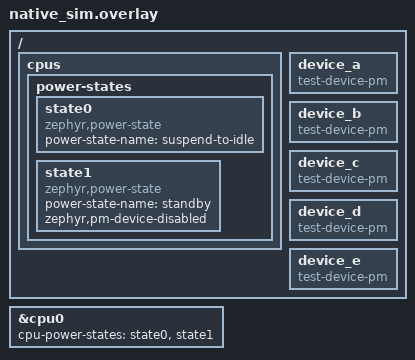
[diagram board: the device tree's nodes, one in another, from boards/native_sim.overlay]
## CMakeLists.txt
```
# Copyright (c) 2020 Intel Corporation.
# Copyright 2026 NXP
# SPDX-License-Identifier: Apache-2.0

cmake_minimum_required(VERSION 3.28.0)
find_package(Zephyr REQUIRED HINTS $ENV{ZEPHYR_BASE})
project(power_management_test)

FILE(GLOB app_sources src/*.c)
target_sources(app PRIVATE ${app_sources})

if(CONFIG_TEST_PM_TIMER_RESTART)
  if(NOT LINKER MATCHES "^(ld|lld)$")
    message(FATAL_ERROR "The timer resume test requires GNU ld or LLD for --wrap")
  endif()
  target_link_options(app PUBLIC "LINKER:--wrap=sys_clock_idle_exit")
endif()

target_include_directories(app
  PRIVATE
    ${ZEPHYR_BASE}/kernel/include
    ${ZEPHYR_BASE}/arch/${ARCH}/include
)
```

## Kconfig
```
# Copyright (c) 2023 Nordic Semiconductor ASA
# Copyright 2026 NXP
# SPDX-License-Identifier: Apache-2.0

menu "Zephyr"
source "Kconfig.zephyr"
endmenu

config TEST_PROVIDE_PM_HOOKS
	bool "Provide PM hooks for test purposes"
	default y
	select HAS_PM

config TEST_PM_TIMER_RESTART
	bool "Test timer and PM resume ordering"
	# The test relies on SysTick stopping its cycle counter for an infinite idle
	# timeout with no LPM companion, then restarting it on idle exit.
	depends on CORTEX_M_SYSTICK
```

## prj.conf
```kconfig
CONFIG_ZTEST=y
CONFIG_PM=y
CONFIG_PM_DEVICE=y
CONFIG_PM_DEVICE_RUNTIME=y
CONFIG_PM_POLICY_CUSTOM=y
CONFIG_MP_MAX_NUM_CPUS=1
CONFIG_PM_DEVICE_SYSTEM_MANAGED=y
CONFIG_STATS=y
CONFIG_PM_STATS=y
```

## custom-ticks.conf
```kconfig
CONFIG_ZTEST=y
CONFIG_PM=y
CONFIG_PM_DEVICE=y
CONFIG_PM_DEVICE_RUNTIME=y
CONFIG_PM_POLICY_CUSTOM=y
CONFIG_MP_MAX_NUM_CPUS=1
CONFIG_PM_DEVICE_SYSTEM_MANAGED=y
CONFIG_STATS=y
CONFIG_PM_STATS=y
CONFIG_PM_CUSTOM_TICKS_HOOK=y
```

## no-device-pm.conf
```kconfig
CONFIG_ZTEST=y
CONFIG_PM=y
CONFIG_PM_DEVICE=y
CONFIG_PM_DEVICE_RUNTIME=y
CONFIG_PM_POLICY_CUSTOM=y
CONFIG_PM_DEVICE_SYSTEM_MANAGED=n
CONFIG_MP_MAX_NUM_CPUS=1
```

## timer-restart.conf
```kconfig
# SPDX-FileCopyrightText: Copyright 2026 NXP
# SPDX-License-Identifier: Apache-2.0

CONFIG_ZTEST=y
CONFIG_PM=y
CONFIG_PM_DEVICE=y
CONFIG_PM_DEVICE_RUNTIME=y
CONFIG_PM_POLICY_CUSTOM=y
CONFIG_MP_MAX_NUM_CPUS=1
CONFIG_PM_DEVICE_SYSTEM_MANAGED=y
CONFIG_STATS=y
CONFIG_PM_STATS=y
CONFIG_TEST_PM_TIMER_RESTART=y
CONFIG_SYSTEM_TIMER_LPM_COMPANION_NONE=y
```

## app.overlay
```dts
/*
 * Copyright 2021 Intel Corporation
 *
 * SPDX-License-Identifier: Apache-2.0
 */

/ {
	wakeup_capable_test_dev {
		compatible = "zephyr,wakeup-dev";
		label = "WAKEUP_CAPABLE";
		status = "okay";
		wakeup-source;
	};
};
```

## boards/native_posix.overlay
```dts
/*
 * Copyright (c) 2021 Intel Corporation.
 *
 * SPDX-License-Identifier: Apache-2.0
 */

/ {
	cpus {
		power-states {
			suspend: suspend {
				compatible = "zephyr,power-state";
				power-state-name = "suspend-to-idle";
			};
		};
	};

	device_a: device_a {
		compatible = "test-device-pm";
	};

	device_b: device_b {
		compatible = "test-device-pm";
	};

	device_c: device_c {
		compatible = "test-device-pm";
	};

	device_d: device_d {
		compatible = "test-device-pm";
	};
};

&cpu0 {
	cpu-power-states = <&suspend>;
};
```

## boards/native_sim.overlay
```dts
/*
 * Copyright (c) 2021 Intel Corporation.
 *
 * SPDX-License-Identifier: Apache-2.0
 */

/ {
	cpus {
		power-states {
			state0: state0 {
				compatible = "zephyr,power-state";
				power-state-name = "suspend-to-idle";
			};

			state1: state1 {
				compatible = "zephyr,power-state";
				power-state-name = "standby";
				zephyr,pm-device-disabled;
			};
		};
	};

	device_a: device_a {
		compatible = "test-device-pm";
	};

	device_b: device_b {
		compatible = "test-device-pm";
	};

	device_c: device_c {
		compatible = "test-device-pm";
	};

	device_d: device_d {
		compatible = "test-device-pm";
	};

	device_e: device_e {
		compatible = "test-device-pm";
	};
};

&cpu0 {
	cpu-power-states = <&state0 &state1>;
};
```

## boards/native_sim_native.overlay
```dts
/*
 * Copyright (c) 2021 Intel Corporation.
 *
 * SPDX-License-Identifier: Apache-2.0
 */

/ {
	device_a: device_a {
		compatible = "test-device-pm";
	};

	device_b: device_b {
		compatible = "test-device-pm";
	};

	device_c: device_c {
		compatible = "test-device-pm";
	};

	device_d: device_d {
		compatible = "test-device-pm";
	};
};
```

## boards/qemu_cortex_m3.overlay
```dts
/*
 * SPDX-FileCopyrightText: Copyright 2026 NXP
 *
 * SPDX-License-Identifier: Apache-2.0
 */

/ {
	cpus {
		power-states {
			state0: state0 {
				compatible = "zephyr,power-state";
				power-state-name = "suspend-to-idle";
			};

			state1: state1 {
				compatible = "zephyr,power-state";
				power-state-name = "standby";
				zephyr,pm-device-disabled;
			};
		};
	};

	device_a: device_a {
		compatible = "test-device-pm";
	};

	device_b: device_b {
		compatible = "test-device-pm";
	};

	device_c: device_c {
		compatible = "test-device-pm";
	};

	device_d: device_d {
		compatible = "test-device-pm";
	};

	device_e: device_e {
		compatible = "test-device-pm";
	};
};

&{/cpus/cpu@0} {
	cpu-power-states = <&state0 &state1>;
};
```

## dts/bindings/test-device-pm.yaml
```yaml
# Copyright (c) 2021, Intel Corporation
# SPDX-License-Identifier: Apache-2.0

description: |
    This binding provides resources required to build and run the
    tests/subsys/power/power_mgmt test in Zephyr.

compatible: "test-device-pm"
```

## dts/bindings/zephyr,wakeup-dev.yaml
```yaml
# Copyright (c) 2021 Intel Corporation.
# SPDX-License-Identifier: Apache-2.0

# Properties for Power Management (PM)

description: |
    This binding provides resources required to build and run the
    tests/subsys/power/power_mgmt test in Zephyr.

compatible: "zephyr,wakeup-dev"

include: base.yaml
```

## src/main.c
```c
/*
 * Copyright (c) 2020 Intel Corporation.
 * Copyright 2026 NXP
 *
 * SPDX-License-Identifier: Apache-2.0
 */

#include <zephyr/sys/printk.h>
#include <zephyr/types.h>
#include <zephyr/pm/device.h>
#include <zephyr/pm/device_runtime.h>
#include <zephyr/ztest.h>
#include <ksched.h>
#include <zephyr/kernel.h>
#include <zephyr/drivers/timer/system_timer.h>
#include <zephyr/pm/pm.h>
#include <zephyr/pm/policy.h>
#include "dummy_driver.h"

/**
 * @brief Power Management Tests
 * @defgroup power_tests Power Management
 * @ingroup all_tests
 */

#define SLEEP_MSEC 100
#define SLEEP_TIMEOUT K_MSEC(SLEEP_MSEC)

/* for checking power suspend and resume order between system and devices */
static bool enter_low_power;
static bool notify_app_entry;
static bool notify_app_exit;
static bool set_pm;
static bool leave_idle;
static bool idle_entered;
static bool testing_device_runtime;
static bool testing_device_order;
static bool testing_force_state;
static bool exit_post_ops_called;
static int32_t policy_ticks;
#ifdef CONFIG_TEST_PM_TIMER_RESTART
static bool testing_timer_restart;
static bool resume_timer_progressed;

enum resume_event {
	RESUME_POST_OPS,
	RESUME_TIMER,
	RESUME_DEVICE,
	RESUME_NOTIFY,
};

static enum resume_event resume_events[4];
static size_t resume_event_count;

static void record_resume_event(enum resume_event event)
{
	zassert_false(arch_cpu_irqs_are_enabled(), "Interrupts enabled during resume");
	zassert_true(resume_event_count < ARRAY_SIZE(resume_events),
		     "Too many resume events");
	resume_events[resume_event_count++] = event;
}

void __real_sys_clock_idle_exit(void);

void __wrap_sys_clock_idle_exit(void)
{
	if (testing_timer_restart) {
		record_resume_event(RESUME_TIMER);
	}
	__real_sys_clock_idle_exit();
}

static void notify_timer_test_exit(enum pm_state state)
{
	ARG_UNUSED(state);
	record_resume_event(RESUME_NOTIFY);
}

static struct pm_notifier timer_test_notifier = {
	.state_exit = notify_timer_test_exit,
};
#endif

enum pm_state forced_state;
static const struct device *device_dummy;
static struct dummy_driver_api *api;

static const struct device *const device_a =
	DEVICE_DT_GET(DT_INST(0, test_device_pm));
static const struct device *const device_c =
	DEVICE_DT_GET(DT_INST(2, test_device_pm));

/*
 * This device does not support PM. It is used to check
 * the behavior of the PM subsystem when a device does not
 * support PM.
 */
static const struct device *const device_e =
	DEVICE_DT_GET(DT_INST(4, test_device_pm));

DEVICE_DT_DEFINE(DT_INST(4, test_device_pm), NULL,
		NULL, NULL, NULL,
		PRE_KERNEL_1, CONFIG_KERNEL_INIT_PRIORITY_DEVICE,
		NULL);

/*
 * According with the initialization level, devices A, B and C are
 * initialized in the following order A -> B -> C.
 *
 * The power management subsystem uses this order to suspend and resume
 * devices. Devices are suspended in the reverse order:
 *
 * C -> B -> A
 *
 * While resuming uses the initialization order:
 *
 * A -> B -> C
 *
 * This test checks if these order is correct checking devices A and C states
 * when suspending / resuming device B.
 */

static int device_a_pm_action(const struct device *dev,
		enum pm_device_action pm_action)
{
	ARG_UNUSED(dev);
	ARG_UNUSED(pm_action);

	return 0;
}

PM_DEVICE_DT_DEFINE(DT_INST(0, test_device_pm), device_a_pm_action);

DEVICE_DT_DEFINE(DT_INST(0, test_device_pm), NULL,
		PM_DEVICE_DT_GET(DT_INST(0, test_device_pm)), NULL, NULL,
		PRE_KERNEL_1, CONFIG_KERNEL_INIT_PRIORITY_DEVICE,
		NULL);


static int device_b_pm_action(const struct device *dev,
		enum pm_device_action pm_action)
{
	enum pm_device_state state_a;
	enum pm_device_state state_c;

#ifdef CONFIG_TEST_PM_TIMER_RESTART
	if ((pm_action == PM_DEVICE_ACTION_RESUME) && testing_timer_restart) {
		uint32_t start_cycles = k_cycle_get_32();

		for (volatile uint32_t i = 0U; i < 10000U; i++) {
			arch_nop();
		}

		resume_timer_progressed = k_cycle_get_32() != start_cycles;
		record_resume_event(RESUME_DEVICE);
	}
#endif

	if (!testing_device_order) {
		return 0;
	}

	(void)pm_device_state_get(device_a, &state_a);
	(void)pm_device_state_get(device_c, &state_c);

	switch (pm_action) {
	case PM_DEVICE_ACTION_RESUME:
		/* Check if device C is still suspended */
		zassert_equal(state_c, PM_DEVICE_STATE_SUSPENDED,
				"Inconsistent states");
		/* Check if device A is already active */
		zassert_equal(state_a, PM_DEVICE_STATE_ACTIVE,
				"Inconsistent states");
		break;
	case PM_DEVICE_ACTION_SUSPEND:
		/* Check if device C is already suspended */
		zassert_equal(state_c, PM_DEVICE_STATE_SUSPENDED,
				"Inconsistent states");
		/* Check if device A is still active */
		zassert_equal(state_a, PM_DEVICE_STATE_ACTIVE,
				"Inconsistent states");
		break;
	default:
		break;
	}

	return 0;
}

PM_DEVICE_DT_DEFINE(DT_INST(1, test_device_pm), device_b_pm_action);

DEVICE_DT_DEFINE(DT_INST(1, test_device_pm), NULL,
		PM_DEVICE_DT_GET(DT_INST(1, test_device_pm)), NULL, NULL,
		PRE_KERNEL_2, CONFIG_KERNEL_INIT_PRIORITY_DEVICE,
		NULL);

static int device_c_pm_action(const struct device *dev,
		enum pm_device_action pm_action)
{
	ARG_UNUSED(dev);
	ARG_UNUSED(pm_action);

	return 0;
}

PM_DEVICE_DT_DEFINE(DT_INST(2, test_device_pm), device_c_pm_action);

DEVICE_DT_DEFINE(DT_INST(2, test_device_pm), NULL,
		PM_DEVICE_DT_GET(DT_INST(2, test_device_pm)), NULL, NULL,
		POST_KERNEL, CONFIG_KERNEL_INIT_PRIORITY_DEVICE,
		NULL);

static int device_init_failed(const struct device *dev)
{
	ARG_UNUSED(dev);

	/* Return error to mark device as not ready. */
	return -EIO;
}

static int device_d_pm_action(const struct device *dev,
		enum pm_device_action pm_action)
{
	ARG_UNUSED(dev);
	ARG_UNUSED(pm_action);

	zassert_unreachable("Entered PM handler for unready device");

	return 0;
}

PM_DEVICE_DT_DEFINE(DT_INST(3, test_device_pm), device_d_pm_action);

DEVICE_DT_DEFINE(DT_INST(3, test_device_pm), device_init_failed,
		PM_DEVICE_DT_GET(DT_INST(3, test_device_pm)), NULL, NULL,
		POST_KERNEL, CONFIG_KERNEL_INIT_PRIORITY_DEVICE,
		NULL);

void pm_state_set(enum pm_state state, uint8_t substate_id)
{
	ARG_UNUSED(substate_id);
	ARG_UNUSED(state);

	if (!IS_ENABLED(CONFIG_PM_STATE_SET_IRQ_UNLOCKED)) {
		zassert_equal(_kernel.idle, 0,
			      "PM state set ran before idle wake sentinel was cleared");
	}

#ifdef CONFIG_TEST_PM_TIMER_RESTART
	if (testing_timer_restart) {
		k_spinlock_key_t key = sys_clock_lock();

		sys_clock_idle_enter(SYS_CLOCK_IDLE_FOREVER);
		sys_clock_unlock(key);
		return;
	}
#endif

	enum pm_device_state device_power_state;

#ifndef CONFIG_PM_DEVICE_SYSTEM_MANAGED
	/* Devices shouldn't have changed state because system managed
	 * device power management is not enabled.
	 **/
	pm_device_state_get(device_a, &device_power_state);
	zassert_true(device_power_state == PM_DEVICE_STATE_ACTIVE);

	pm_device_state_get(device_c, &device_power_state);
	zassert_true(device_power_state == PM_DEVICE_STATE_ACTIVE);
#else
	/* If testing device order this function does not need to anything */
	if (testing_device_order) {
		return;
	}

	if (testing_force_state) {
		/* if forced to given power state was called */
		set_pm = true;
		zassert_equal(state, forced_state);
		testing_force_state = false;

		/* We have forced a state that does not trigger device power management.
		 * The device should still be active.
		 */
		pm_device_state_get(device_c, &device_power_state);
		zassert_true(device_power_state == PM_DEVICE_STATE_ACTIVE);
	}

	/* at this point, notify_pm_state_entry() implemented in
	 * this file has been called and set_pm should have been set
	 */
	zassert_true(set_pm == true,
		     "Notification to enter suspend was not sent to the App");

	/* this function is called after devices enter low power state */
	pm_device_state_get(device_dummy, &device_power_state);

	if (testing_device_runtime) {
		/* If device runtime is enable, the device should still be
		 * active
		 */
		zassert_true(device_power_state == PM_DEVICE_STATE_ACTIVE);
	} else {
		/* at this point, devices have been deactivated */
		zassert_false(device_power_state == PM_DEVICE_STATE_ACTIVE);
	}

	/* this function is called when system entering low power state, so
	 * parameter state should not be PM_STATE_ACTIVE
	 */
	zassert_false(state == PM_STATE_ACTIVE,
		      "Entering low power state with a wrong parameter");
#endif
}

void pm_state_exit_post_ops(enum pm_state state, uint8_t substate_id)
{
	ARG_UNUSED(state);
	ARG_UNUSED(substate_id);

	exit_post_ops_called = true;
#ifdef CONFIG_TEST_PM_TIMER_RESTART
	if (testing_timer_restart) {
		record_resume_event(RESUME_POST_OPS);
	}
#endif
	zassert_false(arch_cpu_irqs_are_enabled(),
		      "PM exit post ops ran with interrupts enabled");
}

#ifdef CONFIG_PM_CUSTOM_TICKS_HOOK
/* Ticks reported by the custom hook; -1 means no custom event is pending */
static int64_t custom_ticks = -1;

int64_t pm_policy_next_custom_ticks(void)
{
	return custom_ticks;
}
#endif /* CONFIG_PM_CUSTOM_TICKS_HOOK */

/* Our PM policy handler */
const struct pm_state_info *pm_policy_next_state(uint8_t cpu, int32_t ticks)
{
	const struct pm_state_info *cpu_states;

	policy_ticks = ticks;

	zassert_true(pm_state_cpu_get_all(cpu, &cpu_states) == 2,
		     "There is no power state defined");

	/* make sure this is idle thread */
	zassert_true(z_is_idle_thread_object(_current));
	zassert_true(ticks == _kernel.idle);
	zassert_false(k_can_yield());
	idle_entered = true;

	if (enter_low_power) {
		enter_low_power = false;
		notify_app_entry = true;
		return &cpu_states[0];
	}

	return NULL;
}

/* implement in application, called by idle thread */
static void notify_pm_state_entry(enum pm_state state)
{
	enum pm_device_state device_power_state;

	/* enter suspend */
	zassert_true(notify_app_entry == true,
		     "Notification to enter suspend was not sent to the App");
	zassert_true(z_is_idle_thread_object(_current));
	zassert_equal(state, PM_STATE_SUSPEND_TO_IDLE);

	pm_device_state_get(device_dummy, &device_power_state);
	if (testing_device_runtime || !IS_ENABLED(CONFIG_PM_DEVICE_SYSTEM_MANAGED)) {
		/* If device runtime is enable, the device should still be
		 * active
		 */
		zassert_true(device_power_state == PM_DEVICE_STATE_ACTIVE);
	} else {
		/* at this point, devices should not be active */
		zassert_false(device_power_state == PM_DEVICE_STATE_ACTIVE);
	}
	set_pm = true;
	notify_app_exit = true;
}

/* implement in application, called by idle thread */
static void notify_pm_state_exit(enum pm_state state)
{
	enum pm_device_state device_power_state;

	/* leave suspend */
	zassert_true(notify_app_exit == true,
		     "Notification to leave suspend was not sent to the App");
	zassert_true(z_is_idle_thread_object(_current));
	zassert_equal(state, PM_STATE_SUSPEND_TO_IDLE);

	/* at this point, devices are active again*/
	pm_device_state_get(device_dummy, &device_power_state);
	zassert_equal(device_power_state, PM_DEVICE_STATE_ACTIVE);
	leave_idle = true;

}

/**
 * @brief test power idle
 *
 * @details
 *  - The global idle routine executes when no other work is available
 *  - The idle routine provide a timeout parameter to the suspend routine
 *    indicating the amount of time guaranteed to expire before the next
 *    timeout, pm_policy_next_state() handle this parameter.
 *  - In this case, pm_policy_next_sate() return PM_STATE_ACTIVE,
 *    so there is no low power operation happen.
 *
 * @see pm_policy_next_state()
 *
 * @ingroup power_tests
 * @verifies ZEP-SRS-13-41
 */
ZTEST(power_management_1cpu, test_power_idle)
{
	TC_PRINT("give way to idle thread\n");
	k_sleep(SLEEP_TIMEOUT);
	zassert_true(idle_entered, "Never entered idle thread");
}

/*
 * @brief test that a far future event does not truncate the policy tick count
 *
 * @details
 *  - pm_policy_next_event_ticks() reports the ticks until the next registered
 *    event as an int64_t, while pm_policy_next_state() takes an int32_t.
 *  - An event scheduled beyond the int32_t tick range must therefore be
 *    saturated, not truncated: a truncated value wraps negative, which both
 *    trips the assertions in the PM subsystem and makes the far future event
 *    look nearer than the kernel timeout.
 *  - The nearer kernel timeout must still be the one handed to the policy.
 *
 * @see pm_policy_event_register(), pm_policy_next_event_ticks()
 *
 * @ingroup power_tests
 */
ZTEST(power_management_1cpu, test_next_event_far_future_ticks)
{
	struct pm_policy_event evt;

	policy_ticks = -1;
	idle_entered = false;

	/*
	 * Schedule the event past the int32_t tick range, with a one second
	 * margin so that the remaining tick count is still out of range by the
	 * time the idle thread evaluates it. Using an uptime relative target
	 * keeps this independent of the tick rate.
	 */
	pm_policy_event_register(&evt, k_uptime_ticks() + (int64_t)INT32_MAX +
					      CONFIG_SYS_CLOCK_TICKS_PER_SEC);

	/* give way to idle thread */
	k_sleep(SLEEP_TIMEOUT);

	pm_policy_event_unregister(&evt);

	zassert_true(idle_entered, "Never entered idle thread");
	zassert_true(policy_ticks >= 0,
		     "Far future event truncated to a negative tick count: %d",
		     policy_ticks);
}

#ifdef CONFIG_PM_CUSTOM_TICKS_HOOK
/*
 * @brief test that a far future custom event does not truncate the policy ticks
 *
 * @details
 *  - pm_policy_next_custom_ticks() reports int64_t ticks and has the same
 *    narrowing hazard as pm_policy_next_event_ticks(), so it must be saturated
 *    the same way before reaching pm_policy_next_state().
 *  - Outside of this test the hook reports -1, so every other test in this
 *    configuration also covers the case where one side has nothing pending
 *    while the other carries a real deadline.
 *
 * @see pm_policy_next_custom_ticks()
 *
 * @ingroup power_tests
 */
ZTEST(power_management_1cpu, test_custom_ticks_far_future)
{
	policy_ticks = -1;
	idle_entered = false;

	/*
	 * The hook reports a relative tick count, so put it just past the
	 * int32_t range. The kernel timeout below stays the nearer deadline.
	 */
	custom_ticks = (int64_t)INT32_MAX + CONFIG_SYS_CLOCK_TICKS_PER_SEC;

	/* give way to idle thread */
	k_sleep(SLEEP_TIMEOUT);

	custom_ticks = -1;

	zassert_true(idle_entered, "Never entered idle thread");
	zassert_true(policy_ticks >= 0,
		     "Far future custom event truncated to a negative tick count: %d",
		     policy_ticks);
}
#endif /* CONFIG_PM_CUSTOM_TICKS_HOOK */

static struct pm_notifier notifier = {
	.state_entry = notify_pm_state_entry,
	.state_exit = notify_pm_state_exit,
};

/**
 * @brief test power state transition
 *
 * @details
 *  - The system support control of power state ordering between
 *    subsystems and devices
 *  - The application can control system power state transitions in idle thread
 *    through pm_notify_pm_state_entry and pm_notify_pm_state_exit
 *
 * @see pm_notify_pm_state_entry(), pm_notify_pm_state_exit()
 *
 * @ingroup power_tests
 * @verifies ZEP-SRS-13-1
 * @verifies ZEP-SRS-13-5
 */
ZTEST(power_management_1cpu, test_power_state_trans)
{
	int ret;

	pm_notifier_register(&notifier);
	enter_low_power = true;
	exit_post_ops_called = false;

	ret = pm_device_runtime_disable(device_dummy);
	zassert_true(ret == 0, "Failed to disable device runtime PM");

	/* give way to idle thread */
	k_sleep(SLEEP_TIMEOUT);
	zassert_true(leave_idle);
	zassert_true(exit_post_ops_called);

	ret = pm_device_runtime_enable(device_dummy);
	zassert_true(ret == 0, "Failed to enable device runtime PM");

	pm_notifier_unregister(&notifier);
}

#ifdef CONFIG_TEST_PM_TIMER_RESTART
ZTEST(power_management_1cpu, test_timer_resume_order)
{
	static const enum resume_event early_order[] = {
		RESUME_POST_OPS, RESUME_TIMER, RESUME_DEVICE, RESUME_NOTIFY,
	};
	static const enum resume_event legacy_order[] = {
		RESUME_DEVICE, RESUME_POST_OPS, RESUME_NOTIFY, RESUME_TIMER,
	};
	const enum resume_event *expected =
		IS_ENABLED(CONFIG_PM_EARLY_SYSTEM_TIMER_RESUME) ? early_order : legacy_order;

	pm_notifier_register(&timer_test_notifier);
	enter_low_power = true;
	testing_timer_restart = true;
	resume_timer_progressed = false;
	resume_event_count = 0;

	k_sleep(SLEEP_TIMEOUT);

	testing_timer_restart = false;
	pm_notifier_unregister(&timer_test_notifier);
	zassert_equal(resume_event_count, ARRAY_SIZE(resume_events));
	for (size_t i = 0; i < ARRAY_SIZE(resume_events); i++) {
		zassert_equal(resume_events[i], expected[i], "Unexpected resume event at %zu", i);
	}
	zassert_equal(resume_timer_progressed, IS_ENABLED(CONFIG_PM_EARLY_SYSTEM_TIMER_RESUME),
		      "Unexpected timer state during device resume");
}
#endif

/**
 * @brief notification between system and device
 *
 * @details
 *  - device driver notify its power state change by pm_device_runtime_get and
 *    pm_device_runtime_put_async
 *  - system inform device system power state change through device interface
 *    pm_action_cb
 *
 * @see pm_device_runtime_get(), pm_device_runtime_put_async(),
 *      pm_device_action_run(), pm_device_state_get()
 *
 * @ingroup power_tests
 * @verifies ZEP-SRS-13-3
 * @verifies ZEP-SRS-13-13
 * @verifies ZEP-SRS-13-29
 * @verifies ZEP-SRS-13-30
 * @verifies ZEP-SRS-13-31
 * @verifies ZEP-SRS-13-32
 */
ZTEST(power_management_1cpu, test_power_state_notification)
{
	int ret;
	enum pm_device_state device_power_state;

	pm_notifier_register(&notifier);
	enter_low_power = true;

	ret = api->open(device_dummy);
	zassert_true(ret == 0, "Fail to open device");

	pm_device_state_get(device_dummy, &device_power_state);
	zassert_equal(device_power_state, PM_DEVICE_STATE_ACTIVE);


	/* The device should be kept active even when the system goes idle */
	testing_device_runtime = true;

	k_sleep(SLEEP_TIMEOUT);
	zassert_true(leave_idle);

	api->close(device_dummy);
	pm_device_state_get(device_dummy, &device_power_state);
	zassert_equal(device_power_state, PM_DEVICE_STATE_SUSPENDED);
	pm_notifier_unregister(&notifier);
	testing_device_runtime = false;
}

ZTEST(power_management_1cpu, test_device_order)
{
	zassert_true(device_is_ready(device_a), "device a not ready");
	zassert_true(device_is_ready(device_c), "device c not ready");

	testing_device_order = true;
	enter_low_power = true;

	k_sleep(SLEEP_TIMEOUT);

	testing_device_order = false;
}

/**
 * @brief Test the device busy APIs.
 */
ZTEST(power_management_1cpu, test_busy)
{
	bool busy;

	busy = pm_device_is_any_busy();
	zassert_false(busy);

	pm_device_busy_set(device_dummy);

	busy = pm_device_is_any_busy();
	zassert_true(busy);

	busy = pm_device_is_busy(device_dummy);
	zassert_true(busy);

	pm_device_busy_clear(device_dummy);

	busy = pm_device_is_any_busy();
	zassert_false(busy);

	busy = pm_device_is_busy(device_dummy);
	zassert_false(busy);
}

ZTEST(power_management_1cpu, test_empty_states)
{
	const struct pm_state_info *cpu_states;
	uint8_t state = pm_state_cpu_get_all(1u, &cpu_states);

	zassert_equal(state, 0);
}

/**
 * @brief Verify a forced power state is used on the next idle entry.
 *
 * @details
 * pm_state_force() bypasses the power management policy: the forced state
 * must be the one entered when the system next goes idle, which the suite's
 * state entry hook checks against the forced state.
 *
 * @see pm_state_force()
 *
 * @ingroup power_tests
 * @verifies ZEP-SRS-13-7
 */
ZTEST(power_management_1cpu, test_force_state)
{
	const struct pm_state_info *cpu_states;

	pm_state_cpu_get_all(0, &cpu_states);
	forced_state = cpu_states[1].state;
	bool ret = pm_state_force(0, &cpu_states[1]);

	zassert_equal(ret, true, "Error in force state");

	testing_force_state = true;
	k_sleep(K_SECONDS(1U));
}

ZTEST(power_management_1cpu, test_device_without_pm)
{
	pm_device_busy_set(device_e);

	/* Since this device does not support PM, it should not be set busy */
	zassert_false(pm_device_is_busy(device_e));

	/* No device should be busy */
	zassert_false(pm_device_is_any_busy());

	/* Lets ensure that nothing happens */
	pm_device_busy_clear(device_e);

	/* Check the status. Since PM is enabled but this device does not support it.
	 * It should return -ENOSYS
	 */
	zassert_equal(pm_device_state_get(device_e, NULL), -ENOSYS);

	/* Try to forcefully change the state should also return an error */
	zassert_equal(pm_device_action_run(device_e, PM_DEVICE_ACTION_SUSPEND), -ENOSYS);

	/* Confirming the device is powered */
	zassert_true(pm_device_is_powered(device_e));

	/* Test wakeup functionality */
	zassert_false(pm_device_wakeup_enable(device_e, true));
	zassert_false(pm_device_wakeup_is_enabled(device_e));
}

void power_management_1cpu_teardown(void *data)
{
	pm_notifier_unregister(&notifier);
}

static void *power_management_1cpu_setup(void)
{
	device_dummy = device_get_binding(DUMMY_DRIVER_NAME);
	api = (struct dummy_driver_api *)device_dummy->api;
	return NULL;
}

ZTEST_SUITE(power_management_1cpu, NULL, power_management_1cpu_setup,
			ztest_simple_1cpu_before, ztest_simple_1cpu_after,
			power_management_1cpu_teardown);
```

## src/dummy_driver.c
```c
/*
 * Copyright (c) 2020 Intel Corporation
 *
 * SPDX-License-Identifier: Apache-2.0
 */

#include <zephyr/sys/printk.h>
#include <zephyr/types.h>
#include <zephyr/pm/device.h>
#include <zephyr/pm/device_runtime.h>
#include "dummy_driver.h"

static int dummy_open(const struct device *dev)
{
	return pm_device_runtime_get(dev);
}

static int dummy_close(const struct device *dev)
{
	return pm_device_runtime_put(dev);
}

static int dummy_device_pm_action(const struct device *dev,
				  enum pm_device_action action)
{
	return 0;
}

static const struct dummy_driver_api funcs = {
	.open = dummy_open,
	.close = dummy_close,
};

int dummy_init(const struct device *dev)
{
	return pm_device_runtime_enable(dev);
}

PM_DEVICE_DEFINE(dummy_driver, dummy_device_pm_action);

DEVICE_DEFINE(dummy_driver, DUMMY_DRIVER_NAME, &dummy_init,
	      PM_DEVICE_GET(dummy_driver), NULL, NULL, POST_KERNEL,
	      CONFIG_KERNEL_INIT_PRIORITY_DEFAULT, &funcs);
```

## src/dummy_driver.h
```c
/*
 * Copyright (c) 2020 Intel Corporation.
 *
 * SPDX-License-Identifier: Apache-2.0
 */

#include <zephyr/kernel.h>
#include <zephyr/device.h>
#define DUMMY_DRIVER_NAME	"dummy_driver"

typedef int (*dummy_api_open_t)(const struct device *dev);

typedef int (*dummy_api_close_t)(const struct device *dev);

struct dummy_driver_api {
	dummy_api_open_t open;
	dummy_api_close_t close;
};
```

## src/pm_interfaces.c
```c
/*
 * Copyright (c) 2021 Intel Corporation.
 *
 * SPDX-License-Identifier: Apache-2.0
 */

#include <zephyr.h>
#include <zephyr/types.h>
#include <ztest.h>
#include <ksched.h>
#include <kernel.h>
#include <pm/pm.h>
#include <pm/device_runtime.h>
#include "dummy_driver.h"

static bool enter_low_power;
static bool enter_deep;
static int deep_entered;
static int deep_left;
static bool enter_unknown;
static bool pm_state_force;

const struct device *dev;
struct dummy_driver_api *api;

/* SOC specific power state set function
 * implement here for testing purpose
 */
void pm_power_state_set(struct pm_state_info info)
{
	zassert_not_equal(info.state, PM_STATE_ACTIVE,
			  "Should not be force into active state");
	pm_state_force = true;
}

/* A pm policy for testing purpose */
#define PM_STATE_UNKNOWN 0xFF
struct pm_state_info pm_policy_next_state(int ticks)
{
	struct pm_state_info info;

	memset(&info, 0, sizeof(struct pm_state_info));
	if (enter_low_power) {
		enter_low_power = false;
		if (!pm_constraint_get(PM_STATE_RUNTIME_IDLE)) {
			info.state = PM_STATE_ACTIVE;
		} else {
			info.state = PM_STATE_RUNTIME_IDLE;
		}
	} else if (enter_deep) {
		enter_deep = false;
		if (!pm_constraint_get(PM_STATE_SUSPEND_TO_RAM)) {
			info.state = PM_STATE_ACTIVE;
		} else {
			info.state = PM_STATE_SUSPEND_TO_RAM;
		}
	} else if (enter_unknown) {
		enter_unknown = false;
		info.state = PM_STATE_UNKNOWN;
	} else {
		info.state = PM_STATE_ACTIVE;
	}
	return info;
}

/*
 * @brief test pm_system_suspend()
 *
 * @details pm_system_suspend() is called by idle thread, test thread should
 *          not call this interface directly, but can switch to idle thread
 *          by k_sleep()
 *
 * @ingroup power_tests
 */

#define SLEEP_TIMEOUT K_MSEC(100)
void test_pm_system_suspend(void)
{
	enter_low_power = true;
	/* give way to idle thread */
	k_sleep(SLEEP_TIMEOUT);

	enter_low_power = false;
	enter_deep = true;
	k_sleep(SLEEP_TIMEOUT);

	/* entering an unknown power state */
	enter_low_power = false;
	enter_deep = false;
	enter_unknown = true;
	k_sleep(SLEEP_TIMEOUT);

	/* a device fail to enter suspend state,
	 * that will cause system fail to sleep
	 */
	api->refuse_to_sleep(dev);

	enter_low_power = true;
	k_sleep(SLEEP_TIMEOUT);

	enter_deep = true;
	k_sleep(SLEEP_TIMEOUT);
}

/*
 * @brief test pm_power_state_force()
 *
 * @details pm_power state_force() overrides decision made by PM policy,
 *          forcing usage of given power state immediately
 *
 * @ingroup power_tests
 */
void test_pm_power_state_force(void)
{
	struct pm_state_info info;
	struct pm_state_info info_get_active;
	struct pm_state_info info_get;

	pm_state_force = false;
	info.state = PM_STATE_ACTIVE;
	pm_power_state_force(info);
	/* fail to force system enter active status */
	zassert_false(pm_state_force == true, NULL);

	info_get_active = pm_power_state_next_get();
	zassert_equal(info_get_active.state, info.state, NULL);

	info.state = PM_STATE_SUSPEND_TO_RAM;
	pm_power_state_force(info);
	/* success to force system enter suspend-to-ram status */
	zassert_true(pm_state_force == true, NULL);
	info_get = pm_power_state_next_get();
	zassert_not_equal(info_get.state, info_get_active.state, NULL);

	pm_system_resume();
}

static void notify_pm_state_entry(enum pm_state state)
{
	if (state == PM_STATE_SUSPEND_TO_RAM) {
		deep_entered++;
	}
}
static void notify_pm_state_exit(enum pm_state state)
{
	if (state == PM_STATE_SUSPEND_TO_RAM) {
		deep_left++;
	}
}

/*
 * @brief test pm_notifier_register() and pm_notifier_unregister()
 *
 * @details register and unregister a pm_notifier struct, this struct contains
 *          callbacks that are called when the target enters and exits power
 *          states.
 *
 * @ingroup power_tests
 */
void test_pm_notifier(void)
{
	int ret;

	struct pm_notifier notifier_without_callback = {
		.state_entry = NULL,
		.state_exit = NULL,
	};

	struct pm_notifier notifier = {
		.state_entry = notify_pm_state_entry,
		.state_exit = notify_pm_state_exit,
	};

	deep_entered = 0;
	deep_left = 0;

	pm_notifier_register(&notifier_without_callback);
	pm_notifier_register(&notifier);

	enter_low_power = false;
	enter_deep = true;
	k_sleep(SLEEP_TIMEOUT);
	zassert_equal(deep_entered, 1, NULL);
	zassert_equal(deep_left, 1, NULL);

	ret = pm_notifier_unregister(&notifier);
	zassert_equal(ret, 0, NULL);
	ret = pm_notifier_unregister(&notifier);
	zassert_equal(ret, -EINVAL, NULL);
	ret = pm_notifier_unregister(&notifier_without_callback);
	zassert_equal(ret, 0, NULL);
}

#define PM_DEVICE_STATE_UNKNOWN 0xFF
/*
 * @brief test pm_device_state_set()
 *
 * @details Use pm_device_state_set() to set particular device to specific state
 *
 * @ingroup power_tests
 */
void test_pm_device_state_set(void)
{
	int ret;
	enum pm_device_state state;

	pm_device_state_get(dev, &state);
	zassert_equal(state, PM_DEVICE_STATE_ACTIVE, "wrong state");
	/* resume an active device, no error occurs */
	ret = pm_device_state_set(dev, PM_DEVICE_STATE_ACTIVE);
	zassert_equal(ret, -EALREADY, "fail to resume device");
	pm_device_state_get(dev, &state);
	zassert_equal(state, PM_DEVICE_STATE_ACTIVE, "wrong state");
	ret = strcmp(pm_device_state_str(state), "active");
	zassert_true(ret == 0, NULL);

	/* power off
	 * no interface for powering off all devices, use pm_device_state_set()
	 * to power off dummy_device
	 */
	ret = pm_device_state_set(dev, PM_DEVICE_STATE_OFF);
	zassert_true(ret == 0, "fail to power off device");
	pm_device_state_get(dev, &state);
	zassert_equal(state, PM_DEVICE_STATE_OFF, "wrong state %d", state);
	ret = strcmp(pm_device_state_str(state), "off");
	zassert_true(ret == 0, NULL);
	/* re-power off */
	ret = pm_device_state_set(dev, PM_DEVICE_STATE_OFF);
	zassert_equal(ret, -EALREADY, "fail to power off device");
	/* suspend after power off */
	ret = pm_device_state_set(dev, PM_DEVICE_STATE_SUSPENDED);
	zassert_equal(ret, -ENOTSUP, "fail to power off device");

	/* set device in a undefined state */
	ret = pm_device_state_set(dev, PM_DEVICE_STATE_UNKNOWN);
	zassert_equal(ret, -ENOTSUP, "fail to set device state");
	ret = strcmp(pm_device_state_str(PM_DEVICE_STATE_UNKNOWN), "");
	zassert_true(ret == 0, NULL);
}

/*
 * @brief test pm_device_wakeup_enable()
 *
 * @details If a device has the capability of waking up, it can be enable or
 *          disable by pm_device_wakeup_enable()
 *
 * @ingroup power_tests
 */

void test_pm_device_wakeup_enable(void)
{
	bool ret;
	int res;
	struct device *pm_dev;

	pm_dev = (struct device *)DEVICE_DT_GET(DT_INST(0, zephyr_wakeup_dev));
	zassert_not_null(pm_dev, "Failed to get device");

	/* pm_dev is not pm enabled, request this device will get a -ENOTSUP */
	res = pm_device_get(pm_dev);
	zassert_equal(res, -ENOTSUP, NULL);
	/* enable pm_dev */
	pm_device_enable(pm_dev);
	/* re-enable pm_dev, cause pm_dev->pm->work to be scheduled */
	pm_device_enable(pm_dev);
	res = pm_device_get(pm_dev);
	zassert_equal(res, 0, NULL);

	ret = pm_device_wakeup_is_capable(pm_dev);
	zassert_true(ret, "device is not wakeup capable");

	/* dev is not wakeup capable */
	ret = pm_device_wakeup_is_capable(dev);
	zassert_false(ret, "device is wakeup capable");
	ret = pm_device_wakeup_enable((struct device *)dev, true);
	zassert_false(ret, "success to enable wakeup");
	ret = pm_device_wakeup_is_enabled(dev);
	zassert_false(ret, "device wakeup is enabled");

	ret = pm_device_wakeup_enable(pm_dev, true);
	zassert_true(ret, "fail to enable wakeup");
	ret = pm_device_wakeup_is_enabled(pm_dev);
	zassert_true(ret, "device wakeup is not enabled");

	ret = pm_device_wakeup_enable(pm_dev, false);
	zassert_true(ret, "fail to disenable wakeup");
	ret = pm_device_wakeup_is_enabled(pm_dev);
	zassert_false(ret, "device wakeup is not disenabled");

	/* disable pm_dev */
	pm_device_put(pm_dev);
	pm_device_disable(pm_dev);
}

/*
 * @brief test pm_constraint_set(), pm_constraint_release(),
 *        pm_constraint_get()
 *
 * @details set and unset power management constraint to influence
 *          power management policy
 *
 * @ingroup power_tests
 */
void test_pm_constraint(void)
{
	struct pm_notifier notifier = {
		.state_entry = notify_pm_state_entry,
		.state_exit = notify_pm_state_exit,
	};

	deep_entered = 0;
	deep_left = 0;
	pm_notifier_register(&notifier);

	pm_constraint_set(PM_STATE_SUSPEND_TO_RAM);
	enter_low_power = false;
	enter_deep = true;
	k_sleep(SLEEP_TIMEOUT);
	zassert_equal(deep_entered, 0, NULL);
	zassert_equal(deep_left, 0, NULL);

	pm_constraint_release(PM_STATE_SUSPEND_TO_RAM);
	enter_low_power = false;
	enter_deep = true;
	k_sleep(SLEEP_TIMEOUT);
	zassert_equal(deep_entered, 1, NULL);
	zassert_equal(deep_left, 1, NULL);
	pm_notifier_unregister(&notifier);
}

void test_setup(void)
{
	dev = device_get_binding(DUMMY_NAME);
	api = (struct dummy_driver_api *)dev->api;
	api->open(dev);
}

void test_teardown(void)
{
	api->close(dev);
}

void test_main(void)
{
	ztest_test_suite(power_management_test,
			ztest_unit_test_setup_teardown(test_pm_system_suspend,
							test_setup,
							test_teardown),
			ztest_unit_test(test_pm_power_state_force),
			ztest_unit_test(test_pm_notifier),
			ztest_unit_test(test_pm_constraint),
			ztest_unit_test_setup_teardown(test_pm_device_state_set,
							test_setup,
							test_teardown),
			ztest_unit_test_setup_teardown(
				test_pm_device_wakeup_enable,
				test_setup,
				test_teardown)
			);
	ztest_run_test_suite(power_management_test);
}
```
